# DSS_HWA_CFG register map
Vendor: Texas Instruments
Peripheral module from a debugger description file (folder awr2x44p).
Registers are 32-bit, read-only, no defined reset value unless marked. A register's access mark holds for its fields unless they carry their own. Offsets are as the file gives them; lines under a group give offsets from that group; [hi:lo] are bit positions; {n}, {i} and the like mark numbered series; 'fields as' and 'values as' point back to an identical list; <NAME> marks a mode.

## DSS_HWA_CFG
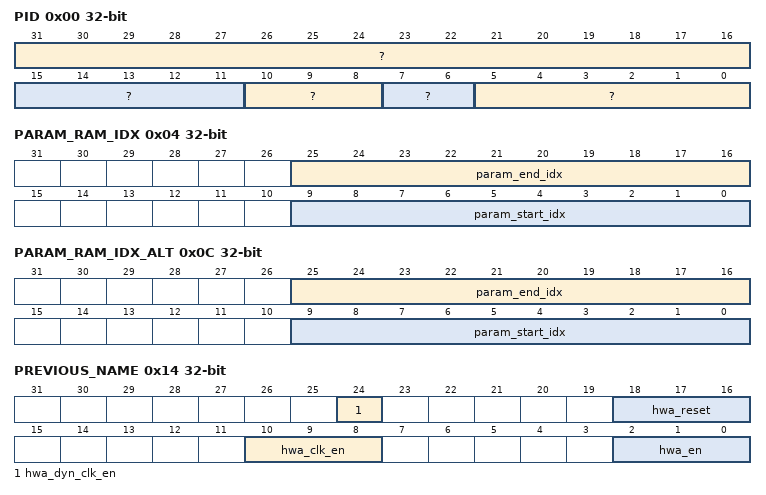
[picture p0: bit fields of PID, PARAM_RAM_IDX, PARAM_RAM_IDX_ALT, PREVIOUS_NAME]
0x00 PID
  [31:16] ?, [15:11] ?, [10:8] ?, [7:6] ?, [5:0] ?
0x04 PARAM_RAM_IDX rw
  [25:16] param_end_idx — The state machine starts at the parameter-set specified by PARAM_START_IDX and loads each parameter-set one after another and runs the accelerator as per that configuration. When the state machine reaches the parameter-set specified by PARAM_ENS_IDX, it loops back to the start index as specified by PARAM_START_IDX.Valid range : 0-63
  [9:0] param_start_idx — The state machine starts at the parameter-set specified by PARAM_START_IDX and loads each parameter-set one after another and runs the accelerator as per that configuration. When the state machine reaches the parameter-set specified by PARAM_ENS_IDX, it loops back to the start index as specified by PARAM_START_IDX..Valid range : 0-63
0x08 PARAM_RAM_LOOP rw
  [11:0] numloops — Number of loops: This register controls the number of times the State Machine will loop through the parameter-sets (from a programmed start index till a programmed end index) and run them. The maximum number of times the loop can be made is run is 4094. A value of zero programmed in this register means that the looping mechanism is disabled.
0x0C PARAM_RAM_IDX_ALT rw
  [25:16] param_end_idx — PARAM_END_IDX for alternate thread
  [9:0] param_start_idx — PARAM_START_IDX for alternate thread
0x10 PARAM_RAM_LOOP_ALT rw
  [11:0] numloops — NUMLOOPS for alternate thread
0x14 PREVIOUS_NAME rw
  [24] hwa_dyn_clk_en — Dynamic Clock-gating Control: Setting this register bit to '1' enables the capability to clock gate the 4 Radar Accelerator core IPs (FFT datapath,CFAR,Memory compression,Local Maxima) based on the ParamSet being executed.
  [18:16] hwa_reset — Software Reset Control: This register provides software reset control for the Radar Hardware Accelerator. The assertion of these register bits by the main processor will bring the Accelerator Engine to a known reset state. This is mostly applicable for resetting the accelerator in case of unexpected behavior. The sequence to be followed in case software reset is to write 111b to this register and then a 000b
  [10:8] hwa_clk_en — Clock-gating Control: This register controls the enable/disable for the clock of the Radar Accelerator. This register bit can be set to 0 to clock-gate the accelerator when not using the accelerator. Before enabling the accelerator or before configuring the accelerator s registers, this register bit should be set first to 111b, so that the clock is available
  [2:0] hwa_en — Enable/Disable Control: A value of ACC_ENABLE = 111b enables the Radar Hardware Accelerator and any other value of the register keeps the Accelerator Engine in disabled state. A 000b to 111b transition is expected to trigger a new Paramset execution
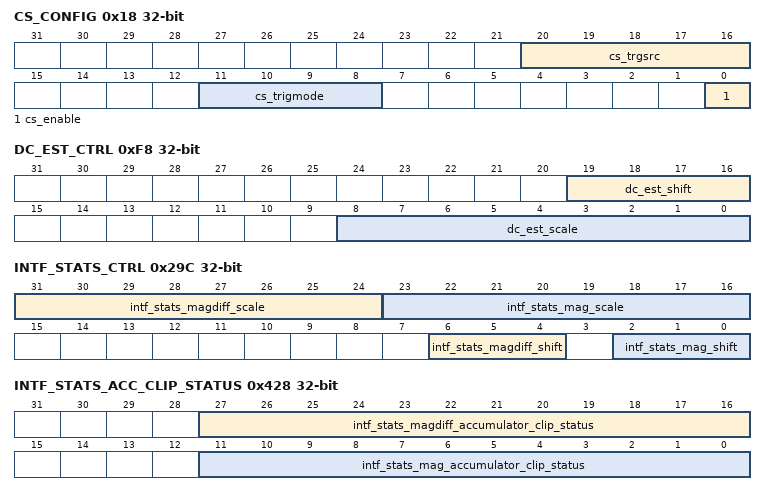
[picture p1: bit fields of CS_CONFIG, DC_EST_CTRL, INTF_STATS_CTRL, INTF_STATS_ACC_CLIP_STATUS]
0x18 CS_CONFIG rw
  [20:16] cs_trgsrc — In case of DMA trigger, this specifies which DMA channel (which bit in DMA2HWA_TRIG register) to wait for In case of HW-based trigger, this specifies which CSI2 trigger signal (out of the 20 possible trigger signals) to wait for
  [11:8] cs_trigmode — Trigger mode for context switching 0011b: DMA-based trigger (used in conjunction with DMA2HWA_TRIGGER and CS_TRIGSRC registers described below) 0100b: Hardware based trigger (used in conjunction with CS_TRIGSRC) Valid programmation 0-19, where 0 selct right most trigger and 19 selects left most trigger below {CSI2A_FRAME_START[1:0],CSI2A_LINE_END[7:0],CSI2B_FRAME_START[1:0],CSI2B_LINE_END[7:0]} 0101b: Software trigger (used in conjunction with CS_FW2ACC_TRIG register described below)
  [0] cs_enable — Master enable for the Conxtext switching feature.Setting this bit will allow context switching to ALT thread if it is enabled in the Param set
0x1C FW2DMA_TRIG rw
  [31:0] fw2dma_trigger — SW Override for HWA Trigger to DMA by the CPU It s a Self clearing bit
0x20 DMA2HWA_TRIG rw
  [31:0] dma2hwa_trigger — DMA trigger register: This register is relevant whenever DMA triggered mode is used (i.e., TRIGMODE = 011b). Whenever a DMA channel has finished copying input samples into the local memory of the accelerator and wants to trigger the accelerator, the procedure to follow is to use a second linked DMA channel to write a 16-bit one-hot signature into this register to trigger the accelerator. In DMA triggered mode, the State Machine keeps monitoring this 32-bit register and waits as long as a specific bit (see DMA2ACC_CHANNEL_TRIGSRC) in this register is zero. The second linked DMA channel writes a one-hot signature that sets the specific bit, so that the State Machine gets triggered and starts the accelerator operations for that parameter-set. It s a Self clearing bit
0x24 SIGDMACH0DONE
  [31:0] SIGDMACH0DONE — Signature for DMA channel 0 completion : 0x0000_0001 Linked DMA can copy from one of these SIG_DMACHx_DONE registers into DMA2HWA_TRIGGER register to set the appropriate register bit to signal the completion of DMA and trigger the accelerator
0x28 SIGDMACH1DONE
  [31:0] SIGDMACH1DONE — Signature for DMA channel 1 completion : 0x0000_0002
0x2C SIGDMACH2DONE
  [31:0] SIGDMACH2DONE — Signature for DMA channel 2 completion : 0x0000_0004
0x30 SIGDMACH3DONE
  [31:0] SIGDMACH3DONE — Signature for DMA channel 3 completion : 0x0000_0008
0x34 SIGDMACH4DONE
  [31:0] SIGDMACH4DONE — Signature for DMA channel 4 completion : 0x0000_0010
0x38 SIGDMACH5DONE
  [31:0] SIGDMACH5DONE — Signature for DMA channel 5 completion : 0x0000_0020
0x3C SIGDMACH6DONE
  [31:0] SIGDMACH6DONE — Signature for DMA channel 6 completion : 0x0000_0040
0x40 SIGDMACH7DONE
  [31:0] SIGDMACH7DONE — Signature for DMA channel 7 completion : 0x0000_0080
0x44 SIGDMACH8DONE
  [31:0] SIGDMACH8DONE — Signature for DMA channel 8 completion : 0x0000_0100
0x48 SIGDMACH9DONE
  [31:0] SIGDMACH9DONE — Signature for DMA channel 9 completion : 0x0000_0200
0x4C SIGDMACH10DONE
  [31:0] SIGDMACH10DONE — Signature for DMA channel 10 completion : 0x0000_0400
0x50 SIGDMACH11DONE
  [31:0] SIGDMACH11DONE — Signature for DMA channel 11 completion : 0x0000_0800
0x54 SIGDMACH12DONE
  [31:0] SIGDMACH12DONE — Signature for DMA channel 12 completion : 0x0000_1000
0x58 SIGDMACH13DONE
  [31:0] SIGDMACH13DONE — Signature for DMA channel 13 completion : 0x0000_2000
0x5C SIGDMACH14DONE
  [31:0] SIGDMACH14DONE — Signature for DMA channel 14 completion : 0x0000_4000
0x60 SIGDMACH15DONE
  [31:0] SIGDMACH15DONE — Signature for DMA channel 15 completion : 0x0000_8000
0x64 SIGDMACH16DONE
  [31:0] SIGDMACH16DONE — Signature for DMA channel 16 completion : 0x0001_0000
0x68 SIGDMACH17DONE
  [31:0] SIGDMACH17DONE — Signature for DMA channel 17 completion : 0x0002_0000
0x6C SIGDMACH18DONE
  [31:0] SIGDMACH18DONE — Signature for DMA channel 18 completion : 0x0004_0000
0x70 SIGDMACH19DONE
  [31:0] SIGDMACH19DONE — Signature for DMA channel 19 completion : 0x0008_0000
0x74 SIGDMACH20DONE
  [31:0] SIGDMACH20DONE — Signature for DMA channel 20 completion : 0x0010_0000
0x78 SIGDMACH21DONE
  [31:0] SIGDMACH21DONE — Signature for DMA channel 21 completion : 0x0020_0000
0x7C SIGDMACH22DONE
  [31:0] SIGDMACH22DONE — Signature for DMA channel 22 completion : 0x0040_0000
0x80 SIGDMACH23DONE
  [31:0] SIGDMACH23DONE — Signature for DMA channel 23 completion : 0x0080_0000
0x84 SIGDMACH24DONE
  [31:0] SIGDMACH24DONE — Signature for DMA channel 24 completion : 0x0100_0000
0x88 SIGDMACH25DONE
  [31:0] SIGDMACH25DONE — Signature for DMA channel 25 completion : 0x0200_0000
0x8C SIGDMACH26DONE
  [31:0] SIGDMACH26DONE — Signature for DMA channel 26 completion : 0x0400_0000
0x90 SIGDMACH27DONE
  [31:0] SIGDMACH27DONE — Signature for DMA channel 27 completion : 0x0800_0000
0x94 SIGDMACH28DONE
  [31:0] SIGDMACH28DONE — Signature for DMA channel 28 completion : 0x1000_0000
0x98 SIGDMACH29DONE
  [31:0] SIGDMACH29DONE — Signature for DMA channel 29 completion : 0x2000_0000
0x9C SIGDMACH30DONE
  [31:0] SIGDMACH30DONE — Signature for DMA channel 30 completion : 0x4000_0000
0xA0 SIGDMACH31DONE
  [31:0] SIGDMACH31DONE — Signature for DMA channel 31 completion : 0x8000_0000
0xA4 FW2HWA_TRIG_0 rw
  [0] fw2hwa_trigger_0 — Software trigger bit 0: This register bit is relevant whenever software triggered mode is used (i.e., TRIGMODE = 001b). The main processor software can set this register bit, so that the State Machine gets triggered and starts the accelerator operations for that parameter-set. It s a Self clearing bit
0xA8 FW2HWA_TRIG_1 rw
  [0] fw2hwa_trigger_1 — Software trigger bit 1: This register bit is relevant whenever software triggered mode is used (i.e., TRIGMODE = 111b). The main processor software can set this register bit, so that the State Machine gets triggered and starts the accelerator operations for that parameter-set. It s a Self clearing bit
0xAC CS_FW2ACC_TRIG rw
  [0] fw2hwa_trigger_cs — CPU can set this register bit to trigger a context switch when CS_TRIGMODE = 101b It s a Self clearing bit
{0xB0+4i} BPM_PATTERN_{i} rw (i=0..6)
  [31:0] bpm_pattern_{i} — BPM pattern [{32i+31}:{32i}]: Specifies the BPM pattern to be used to multiply the input samples if BPM removal is enabled
0xCC BPM_PATTERN_7 rw
  [31:0] bpm_pattern_7 — BPM pattern[255:224]: Specifies the BPM pattern to be used to multiply the input samples if BPM removal is enabled
0xD0 BPM_RATE rw
  [9:0] bpm_rate — BPM rate: Specifies the number of input samples corresponding to each BPM bit. Minimum valid value for this register is 1.
0xD4 PARAM_DONE_SET_STATUS_0
  [31:0] param_done_set_status_0 — Parameter-set done status[31:0]: This read-only status register can be used by the main processor to see which parameter-sets are complete that led to the interrupt to the main processor. The individual bits in this 64-bit status register indicate which of the 64 parameter-sets have completed.
0xD8 PARAM_DONE_SET_STATUS_1
  [31:0] param_done_set_status_1 — Parameter-set done status[63:32]: This read-only status register can be used by the main processor to see which parameter-sets are complete that led to the interrupt to the main processor. The individual bits in this 64-bit status register indicate which of the 64 parameter-sets have completed.
0xDC PARAM_DONE_CLR_0 rw
  [31:0] param_done_status_clr_0 — Status bits in PARAM_DONE_SET_STATUS are not automatically cleared, but they can be individually cleared by writing to 64-bit register PARAM_DONE_CLR. It s a Self clearing bit
0xE0 PARAM_DONE_CLR_1 rw
  [31:0] param_done_status_clr_1 — Status bits in PARAM_DONE_SET_STATUS are not automatically cleared, but they can be individually cleared by writing to 64-bit register PARAM_DONE_CLR. It s a Self clearing bit
0xE4 TRIGGER_SET_STATUS_0
  [31:0] trigger_set_status_0 — Debug register for trigger status[31:0]: This is a read-only status register, which indicates the trigger status of the accelerator, i.e., whether a specific DMA trigger or a CSI or a SW trigger was ever received (refer TRIGMODE in HW_ACC_PARAM register set). The mapping for 32 bits is as given below: {DMA2HWA_TRIGGER[31:0]}
0xE8 TRIGGER_SET_STATUS_1
  [31:0] trigger_set_status_1 — Debug register for trigger status[63:32]: This is a read-only status register, which indicates the trigger status of the accelerator, i.e., whether a specific DMA trigger or a CSI or a SW trigger was ever received (refer TRIGMODE in HW_ACC_PARAM register set). The mapping for 32 bits is as given below: {4'b0,CSI2A_FRAME_START[1:0],CSI2A_LINE_END[7:0],CSI2B_FRAME_START[1:0],CSI2B_LINE_END[7:0],FW2HWA_TRIGGER_CS,FW2HWA_TRIGGER_1,3'b0,FW2HWA_TRIGGER_0,1'b1}
0xEC TRIGGER_SET_IN_CLR_0 rw
  [0] trigger_set_in_clr_0 — Clear trigger_set_status : This register-bit when set clears the trigger status register TRIGGER_SET_STATUS_0 described above It s a Self clearing bit
0xF0 TRIGGER_SET_IN_CLR_1 rw
  [0] trigger_set_in_clr_1 — Clear trigger_set_status : This register-bit when set clears the trigger status register TRIGGER_SET_STATUS_1 described above It s a Self clearing bit
0xF4 DC_EST_RESET_SW rw
  [0] dc_est_reset_sw — Reset for all 12 DC estimation accumulators It s a Self clearing bit
0xF8 DC_EST_CTRL rw
  [19:16] dc_est_shift — Programmable shift applied to all 12 accumulator outputs. Cannot be bypassed. Output shifted by 2^(8 + 6+DCEST_SHIFT). For DCEST_SHIFT = 15 also gives 2^(28) and not 29 (saturate at 28)
  [8:0] dc_est_scale — 9-bit scale applied to all 12 accumulators. Multiplies the accumulator output by DCEST_SCALE/256.This is followed by right shift and truncation. Default value is 256 giving a scale of 1.0. Setting it to 128, gives a scale of 0.5
{0xFC+4i} DC_EST_I_{i}_VAL (i=0..11)
  [23:0] dc_est_i_{i}_val — This read only register provide the DC estimates I for bcnt= {i}
{0x12C+4i} DC_EST_Q_{i}_VAL (i=0..11)
  [23:0] dc_est_q_{i}_val — This read only register provide the DC estimates Q for bcnt= {i}
{0x15C+8i} DC_ACC_I_{i}_VAL_LSB (i=0..11)
  [31:0] dc_acc_i_{i}_val_lsb — This read only register provide the LSB 32 bits value of DC accumulator I channel value for bcnt={i}
{0x160+8i} DC_ACC_I_{i}_VAL_MSB (i=0..11)
  [3:0] dc_acc_i_{i}_val_msb — This read only register provide the MSB 4 bits value of DC accumulator I channel value for bcnt={i}
{0x1BC+8i} DC_ACC_Q_{i}_VAL_LSB (i=0..11)
  [31:0] dc_acc_q_{i}_val_lsb — This read only register provide the LSB 32 bits value of DC accumulator Q channel value for bcnt={i}
{0x1C0+8i} DC_ACC_Q_{i}_VAL_MSB (i=0..11)
  [3:0] dc_acc_q_{i}_val_msb — This read only register provide the MSB 4 bits value of DC accumulator Q channel value for bcnt={i}
0x21C DC_ACC_CLIP_STATUS
  [11:0] dc_acc_clip_status — This register contains the clip status of both I/Q of DC accumulators 0 to 11
0x220 DC_EST_CLIP_STATUS
  [11:0] dc_est_clip_status — This register contains the clip status of DC estimates (both I & Q combined)
0x224 DC_I0_SW rw
  [23:0] dc_i0_sw — SW programmed DC I value(for bcnt =0 ) used in DC subtraction
0x228 DC_I1_SW rw
  [23:0] dc_i1_sw — SW programmed DC I value(for bcnt =1) used in DC subtraction
0x22C DC_I2_SW rw
  [23:0] dc_i2_sw — SW programmed DC I value(for bcnt =2 ) used in DC subtraction
0x230 DC_I3_SW rw
  [23:0] dc_i3_sw — SW programmed DC I value(for bcnt =3) used in DC subtraction
{0x224+4i} DC_I{i}_SW rw (i=4..7)
  [23:0] dc_i{i}_sw — SW programmed DC I value(for bcnt ={i} ) used in DC subtraction
0x244 DC_I8_SW rw
  [23:0] dc_i8_sw — SW programmed DC I value(for bcnt =8) used in DC subtraction
0x248 DC_I9_SW rw
  [23:0] dc_i9_sw — SW programmed DC I value(for bcnt =9 ) used in DC subtraction
0x24C DC_I10_SW rw
  [23:0] dc_i10_sw — SW programmed DC I value(for bcnt =10 ) used in DC subtraction
0x250 DC_I11_SW rw
  [23:0] dc_i11_sw — SW programmed DC I value(for bcnt =11) used in DC subtraction
0x254 DC_Q0_SW rw
  [23:0] dc_q0_sw — SW programmed DC Q value(for bcnt =0 ) used in DC subtraction
0x258 DC_Q1_SW rw
  [23:0] dc_q1_sw — SW programmed DC Q value(for bcnt =1) used in DC subtraction
0x25C DC_Q2_SW rw
  [23:0] dc_q2_sw — SW programmed DC Q value(for bcnt =2 ) used in DC subtraction
0x260 DC_Q3_SW rw
  [23:0] dc_q3_sw — SW programmed DC Q value(for bcnt =3) used in DC subtraction
{0x254+4i} DC_Q{i}_SW rw (i=4..7)
  [23:0] dc_q{i}_sw — SW programmed DC Q value(for bcnt ={i} ) used in DC subtraction
0x274 DC_Q8_SW rw
  [23:0] dc_q8_sw — SW programmed DC Q value(for bcnt =8) used in DC subtraction
0x278 DC_Q9_SW rw
  [23:0] dc_q9_sw — SW programmed DC Q value(for bcnt =9 ) used in DC subtraction
0x27C DC_Q10_SW rw
  [23:0] dc_q10_sw — SW programmed DC Q value(for bcnt =10 ) used in DC subtraction
0x280 DC_Q11_SW rw
  [23:0] dc_q11_sw — SW programmed DC Q value(for bcnt =11) used in DC subtraction
0x284 DC_SUB_CLIP
  [0] DC_SUB_CLIP — Indicates the DC subtraction clip status
{0x280+4i} DC_RESERVED_{i} rw (i=2..5)
  [31:0] dc_sub_reserved_{i} — Reserved for future addition
0x298 INTF_STATS_RESET_SW rw
  [0] intf_stats_reset_sw — SW reset for Interference stats module. It s a self clearing bit.
0x29C INTF_STATS_CTRL rw
  [31:24] intf_stats_magdiff_scale — Unsigned scaler (5.3) applied to INTERFSUM_MAGDIFFn from interference statistics block. Default 8= scale of 1.0
  [23:16] intf_stats_mag_scale — Unsigned scaler (5.3) applied to INTERFSUM_MAGn from interference statistics block. Default 8= scale of 1.0
  [6:4] intf_stats_magdiff_shift — Right shift applied after scaling - 2^(6+INTERFSUM_MAGDIFF_SHIFT). Can t be more than 2^(12).
  [2:0] intf_stats_mag_shift — Right shift applied after scaling - 2^(6+INTERSUM_MAGS_SHIFT). Can t be more than 2^(12).
{0x2A0+4i} INTF_LOC_THRESH_MAG{i}_VAL (i=0..11)
  [23:0] intf_loc_thresh_mag{i}_val — Interference magnitude threshold value from Interference stats module ( read only) for bcnt ={i}
{0x2D0+4i} INTF_LOC_THRESH_MAGDIFF{i}_VAL (i=0..11)
  [23:0] intf_loc_thresh_magdiff{i}_val — Interference magnitude difference threshold value from Interference stats module ( read only) for bcnt ={i}
0x300 INTF_LOC_COUNT_ALL_CHIRP
  [11:0] intf_loc_count_all_chirp — Number of samples that exceeded the threshold in a chirp
0x304 INTF_LOC_COUNT_ALL_FRAME
  [19:0] intf_loc_count_all_frame — Number of samples that exceeded the threshold in a frame
0x308 INTF_STATS_MAG_ACC_0_LSB
  [31:0] intf_stats_mag_acc_0_lsb — This read only register contains the accumulator value of interference magnitude(LSB 32 bits) for bcnt = 0
0x30C INTF_STATS_MAG_ACC_0_MSB
  [3:0] intf_stats_mag_acc_0_msb — This read only register contains the accumulator value of interference magnitude(MSB 4 bits) for bcnt = 0
0x310 INTF_STATS_MAG_ACC_1_LSB
  [31:0] intf_stats_mag_acc_1_lsb — This read only contains the accumulator value of interference magnitude (LSB 32 bits) for bcnt = 1
0x314 INTF_STATS_MAG_ACC_1_MSB
  [3:0] intf_stats_mag_acc_1_msb — This read only contains the accumulator value of interference magnitude (MSB 4 bits) for bcnt = 1
0x318 INTF_STATS_MAG_ACC_2_LSB
  [31:0] intf_stats_mag_acc_2_lsb — This read only contains the accumulator value of interference magnitude (LSB 32 bits) for bcnt = 2
0x31C INTF_STATS_MAG_ACC_2_MSB
  [3:0] intf_stats_mag_acc_2_msb — This read only register contains the accumulator value of interference magnitude (MSB 4 bits) for bcnt = 2
0x320 INTF_STATS_MAG_ACC_3_LSB
  [31:0] intf_stats_mag_acc_3_lsb — This read only register contains the accumulator value of the interference magnitude( for LSB 32 bits) for bcnt = 3
0x324 INTF_STATS_MAG_ACC_3_MSB
  [3:0] intf_stats_mag_acc_3_msb — This read only register contains the accumulator value of the interference magnitude(for MSB 4 bits) for bcnt = 3
{0x308+8i} INTF_STATS_MAG_ACC_{i}_LSB (i=4..9)
  [31:0] intf_stats_mag_acc_{i}_lsb — This read only register contains the accumulator value of the interference magnitude (LSB 32 bits) for bcnt = {i}
{0x30C+8i} INTF_STATS_MAG_ACC_{i}_MSB (i=4..6)
  [3:0] intf_stats_mag_acc_{i}_msb — This read only register contains the accumulator value of the interference magnitude (MSB 4 bits)for bcnt = {i}
0x344 INTF_STATS_MAG_ACC_7_MSB
  [3:0] intf_stats_mag_acc_7_msb — This read only register contains the accumulator value of the interference magnitude (MSB4 bits)for bcnt = 7
{0x30C+8i} INTF_STATS_MAG_ACC_{i}_MSB (i=8..11)
  [3:0] intf_stats_mag_acc_{i}_msb — This read only register contains the accumulator value of the interference magnitude (MSB 4 bits) for bcnt = {i}
0x358 INTF_STATS_MAG_ACC_10_LSB
  [31:0] intf_stats_mag_acc_10_lsb — This read only register contains the accumulator value of the interference magnitude (LSB 32 bits)for bcnt = 10
0x360 INTF_STATS_MAG_ACC_11_LSB
  [31:0] intf_stats_mag_acc_11_lsb — This read only register contains the accumulator value of the interference magnitude (LSB 32 bits)for bcnt = 11
{0x368+8i} INTF_STATS_MAGDIFF_ACC_{i}_LSB (i=0..3)
  [31:0] intf_stats_magdiff_acc_{i}_lsb — This read only register contains the accumulator value of the interference magnitude difference (LSB 32 bits) for bcnt = {i}
{0x36C+8i} INTF_STATS_MAGDIFF_ACC_{i}_MSB (i=0..11)
  [3:0] intf_stats_magdiff_acc_{i}_msb — This read only register contains the accumulator value of the interference magnitude difference (MSB 4 bits) for bcnt = {i}
0x388 INTF_STATS_MAGDIFF_ACC_4_LSB
  [31:0] intf_stats_magdiff_acc_4_lsb — This read only register contains the accumulator value of the interference magnitude difference (LSB 32 bits) accumulator for bcnt = 4
{0x368+8i} INTF_STATS_MAGDIFF_ACC_{i}_LSB (i=5..11)
  fields as INTF_STATS_MAGDIFF_ACC_0_LSB
{0x3C8+4i} INTF_LOC_THRESH_MAG{i}_SW rw (i=0..11)
  [23:0] intf_loc_thresh_mag{i}_sw — SW programmed interface threshold magnitude for bcnt={i}
{0x3F8+4i} INTF_LOC_THRESH_MAGDIFF{i}_SW rw (i=0..11)
  [23:0] intf_loc_thresh_magdiff{i}_sw — SW programmed interface threshold magnitude difference for bcnt={i}
0x428 INTF_STATS_ACC_CLIP_STATUS
  [27:16] intf_stats_magdiff_accumulator_clip_status — Interference magnitue difference accumulator Clip status
  [11:0] intf_stats_mag_accumulator_clip_status — Interference magnitue accumulator Clip status
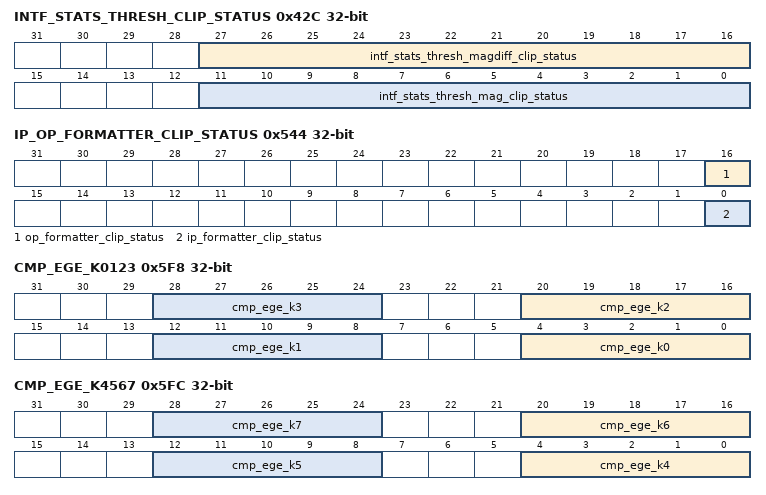
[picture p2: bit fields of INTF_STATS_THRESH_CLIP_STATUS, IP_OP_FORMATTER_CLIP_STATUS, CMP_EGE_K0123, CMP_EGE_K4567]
0x42C INTF_STATS_THRESH_CLIP_STATUS
  [27:16] intf_stats_thresh_magdiff_clip_status — Interference magnitude difference threshold Clip status
  [11:0] intf_stats_thresh_mag_clip_status — Interference magnitude threshold Clip status
0x430 INTF_MITG_WINDOW_PARAM_0 rw
  [4:0] intf_mitg_window_param_0 — This is a programmable array of window parameters. Each window parameter is an unsigned 5 bit integer. The total length of the array is 5. The BFR of the array is given by the matlab code : val = round(hanning(12)*32) INTF_MITG_WINDOW_PARAM = val(1:5);
{0x430+4i} INTF_MITG_WINDOW_PARAM_{i} rw (i=1..4)
  [4:0] intf_mitg_window_param_{i} — Refer description of INTF_MITG_WINDOW_PARAM_0
0x444 INTF_STATS_SUM_MAG_VAL
  [23:0] intf_stats_sum_mag_val — Indicates the sum of mag values ; Only Configured BCNT mag values are added
0x448 INTF_STATS_SUM_MAG_VAL_CLIP_STATUS
  [0] intf_stats_sum_mag_val_clip_status — Indicates the clip status of sum of mag values
0x44C INTF_STATS_SUM_MAGDIFF_VAL
  [23:0] intf_stats_sum_magdiff_val — Indicates the sum of magdiff values ; Only Configured BCNT magdiff values are added
0x450 INTF_STATS_SUM_MAGDIFF_VAL_CLIP_STATUS
  [0] intf_stats_sum_magdiff_val_clip_status — indicates the clip status of sum of magdiff values
0x454 INTERF_RESERVED_5 rw
  [31:0] interf_reserved_5 — Reserved for future addition
{0x458+4i} ICMULT_SCALE{i} rw (i=0..11)
  [20:0] icmult_scale{i} — Complex scalars used in CMULT_MODE = 0101, 0110 & 0111 In CMULT_MODE : 0101 , If set CMULT_SCALE_EN is 1, the input samples are multiplied by a different complex scalar ICMULTSCALE0, QMULTSCALE0 to ICMULTSCALE11, QMULTSCALE11 per-iteration based on REG_BCNT. Else, a constant complex scalar ICMULTSCALE0 and QCMULTSCALE0 is applied to all sample across all iterations. In CMULT_MODE : 0110 or 0111, if CMULT_SCALE_EN is 1, then input samples are multiplied successively by ICMULTSCALE0, QMULTSCALE0 to ICMULTSCALE11, QMULTSCALE11 per iteration. Complex scalar to be multiplier is ACNT modulo 12.
{0x488+4i} QCMULT_SCALE{i} rw (i=0..11)
  [20:0] qcmult_scale{i} — Complex scalars used in CMULT_MODE = 0101, 0110 & 0111 In CMULT_MODE : 0101 , If set CMULT_SCALE_EN is 1, the input samples are multiplied by a different complex scalar ICMULTSCALE0, QMULTSCALE0 to ICMULTSCALE11, QMULTSCALE11 per-iteration based on REG_BCNT. Else, a constant complex scalar ICMULTSCALE0 and QCMULTSCALE0 is applied to all sample across all iterations. In CMULT_MODE : 0110 or 0111, if CMULT_SCALE_EN is 1, then input samples are multiplied successively by ICMULTSCALE0, QMULTSCALE0 to ICMULTSCALE11, QMULTSCALE11 per iteration. Complex scalar to be multiplier is ACNT modulo 12.
0x4B8 TWID_INCR_DELTA_FRAC rw
  [9:0] twid_incr_delta_frac — Used in complex multiplier mode 10 Delta Fractional frequency increment per param-set looping Instantaneous frequency is (TWIDINCR << 10) +TWID_INCR_DELTA_ FRAC*c, c is current execution count of the parameter set.
0x4BC RECWIN_RESET_SW rw
  [0] recwin_reset_sw — This resets the param set counter / execution counter used in Complex multiplier mode 8 . It s a self clearing bit.
0x4C0 TWID_INCR_DELTA_FRAC_RESET_SW rw
  [0] twid_incr_delta_frac_reset_sw — This resets the param set counter used in Complex multiplier mode 10 . It s a Self clearing bit
0x4C4 TWID_INCR_DELTA_FRAC_CLIP_STATUS
  [0] twid_incr_delta_frac_clip_status — Indicates the clip status for TWID_INCR_DELTA_FRAC accumulator
0x4C8 RECWIN_INIT_KVAL rw
  [11:0] recwin_init_kval — Indicates the initialization value of execution counter in recursive window mode . Execution counter value is initialized when recwin_reset_sw is 1'b1
0x4CC CMULT_RESERVED_2 rw
  [31:0] cmult_reserved_2 — Reserved for future addition
0x4D0 CHAN_COMB_SIZE rw
  [7:0] chan_comb_size — Number of samples after combination
{0x4D4+4i} CHAN_COMB_VEC_{i} rw (i=0..7)
  [31:0] chan_comb_vec_{i} — Channel combination MASK for {32i} to {32i+31} samples Vector indicating the samples indices that need to be combined. A 01 or 10 transition demarcates the groups. if CHAN_COMB_VEC = 0xF030000000000000 sums the first 4 samples and outputs one sample, sums 5th-9th samples and passes one sample, combines 10th-12th samples, outputs one sample and then streams the rest of the input
0x4F4 CHANNEL_COMB_CLIP_STATUS
  [0] channel_comb_clip_status — Indicates the clip status of the channel combination
0x4F8 ZERO_INSERT_NUM rw
  [7:0] zero_insert_num — Number of zeros to be inserted in an iteration
{0x4FC+4i} ZERO_INSERT_MASK_{i} rw (i=0..5)
  [31:0] zero_insert_mask_{i} — Zero insert mask for samples {32i} to {32i+31} A bit-field of 0 inserts a zero at location based on bit-field index. 1 means the input is passed through. Up-stream and down-stream processing is stalled during the zero insertion
0x514 ZERO_INSERT_MASK_6 rw
  [31:0] zero_insert_mask_6 — Zero insert mask for samples 192 to 223 A bit field of 0 inserts a zero at location based on bit-field index. 1 means the input is passed through. Up-stream and down-stream processing is stalled during the zero insertion
0x518 ZERO_INSERT_MASK_7 rw
  [31:0] zero_insert_mask_7 — Zero insert mask for samples 224 to 255 A bit-field of 0 inserts a zero at location based on bit-field index. 1 means the input is passed through. Up-stream and down-stream processing is stalled during the zero insertion
{0x518+4i} ZERO_INSERT_RESERVED_{i} rw (i=1..4)
  [31:0] zero_insert_reserved_{i} — Reserved for future addition
0x52C LFSR_SEED rw
  [28:0] lfsr_seed — Seed for LFSR (random pattern): For twiddle factor dithering, there is an LFSR that is used, whose seed value is loaded by writing to this 29-bit LFSRSEED register. The LFSRSEED register should be set to any non-zero value, say 0x1234567
0x530 LFSR_LOAD rw
  [0] lfsr_load — Its self clearing bit . It should be set for loading the LFSR_SEED. It s a self clearing bit
0x534 DITHER_TWID_EN rw
  [0] dither_twid_en — Twiddle factor dithering enable: This register-bit is used to enable and disable dithering of twiddle factors in the FFT. The twiddle factors are 24-bits wide (24-bits for each I and Q), but they are quantized to 21-bits before twiddle factor multiplication. This quantization is implemented with dithering on the LSB, to avoid periodic quantization pattern affecting SFDR performance of the FFT. TI recommends keeping this register bit set to 1 (for example, dithering enabled), with appropriate LSFR seed loaded (see the following).
0x538 FFT_CLIP
  [12:0] fft_clip — FFT Clip Status (read-only): This is a read-only status register, which indicates any saturation/clipping events that have happened in the FFT butterfly stages. Note that each of the individual butterfly stages in the FFT can be programmed to either saturate the MSB or round the LSB. Whenever saturation of MSB is used in any stage, there is a possibility that that stage can saturate or clip samples. In that case, this saturation event is indicated in the corresponding bit in this status register, so that the Cortex-R4F processor can read it. If multiple FFTs are performed, this status register includes any saturation events happening in any of them. This status register can only be cleared by the R4F, by setting another single-bit register CLR_FFTCLIP, so that the saturation status indication gets cleared back to 0 and any subsequent saturation events can be freshly monitored. The MSB of this register indicates clip status corresponding to the radix 3 butterfly.
0x53C CLR_FFTCLIP rw
  [0] clr_fftclip — Clear FFT Clip Status register: This register bit, when set, clears the FFTCLIP register. It s a self clearing bit
0x540 CLR_CLIP_MISC rw
  [0] clr_clip_status — This clears the following clip register channel_comb_clip_status dc_acc_clip_status dc_est_clip_status intf_stats_mag_accumulator_clip_status intf_stats_magdiff_accumulator_clip_status intf_stats_thresh_mag_clip_status intf_stats_thresh_magdiff_clip_status twid_incr_delta_frac_clip_status ip_formatter_clip_status op_formatter_clip_status intf_stats_sum_mag_val_clip_status intf_stats_sum_magdiff_val_clip_status dc_sub_clip Its a self clearing bit
0x544 IP_OP_FORMATTER_CLIP_STATUS
  [16] op_formatter_clip_status — Indicates the output formatter clip status
  [0] ip_formatter_clip_status — Indicates the input formatter clip status
{0x544+4i} FFT_RESERVED_{i} rw (i=1..3)
  [31:0] fft_reserved_{i} — Reserved for future addition
{0x550+4i} MAX{i}_VALUE (i=1..4)
  [23:0] max{i}_value — These registers contain the max value on a per-iteration basis. These registers are meaningful only when Magnitude or Log-Magnitude is enabled. Only the max values for up to four iterations are recorded in these registers. For larger number of iterations, max values are wriiten into destination memory by configuring FFT_OUTPUT_MODE
{0x560+4i} MAX{i}_INDEX (i=1..4)
  [11:0] max{i}_index — These registers contain the max index on a per-iteration basis, corresponding to each max value in the MAXn_VALUE registers.
{0x56C+8i} I_SUM{i}_LSB (i=1..4)
  [31:0] i_sum{i}_lsb — I Sum value {i} LSB 32 bits These registers contain the sum of the I outputs and Q outputs on a per-iteration basis. Only the statistics for up to four iterations are recorded in these registers. For larger number of iterations, use statistics output mode (FFT_OUTPUT_MODE ) to write to destination memory
{0x570+8i} I_SUM{i}_MSB (i=1..4)
  [3:0] i_sum{i}_msb — I Sum value {i} MSB 4 bits These registers contain the sum of the I outputs and Q outputs on a per-iteration basis. Only the statistics for up to four iterations are recorded in these registers. For larger number of iterations, use statistics output mode (FFT_OUTPUT_MODE ) to write to destination memory
{0x58C+8i} Q_SUM{i}_LSB (i=1..4)
  [31:0] q_sum{i}_lsb — Q Sum value {i} LSB 32 bits These registers contain the sum of the I outputs and Q outputs on a per-iteration basis. Only the statistics for up to four iterations are recorded in these registers. For larger number of iterations, use statistics output mode (FFT_OUTPUT_MODE ) to write to destination memory
{0x590+8i} Q_SUM{i}_MSB (i=1..4)
  [3:0] q_sum{i}_msb — Q Sum value {i} MSB 4 bits These registers contain the sum of the I outputs and Q outputs on a per-iteration basis. Only the statistics for up to four iterations are recorded in these registers. For larger number of iterations, use statistics output mode (FFT_OUTPUT_MODE ) to write to destination memory
0x5B4 FFTSUMDIV rw
  [4:0] fftsumdiv — Right-shifting for Sum statistic: This register specifies the number of bits to right-shift the sum statistic before it is written to destination memory. The internal sum statistic register is 36-bits wide (allowing 12 bits of MSB growth of the 24-bit data path), but this statistics value needs to be scaled down to 24 bits to match the data path width going to the Output Formatter. This register specifies how many LSBs to drop to convert the sum statistics to 24-bit value.
0x5B8 MAX2D_OFFSET_DIM1 rw
  [23:0] max2d_offset_dim1 — Offset to be added to dimension 1 Maxima results. This offset will be applied to all the maxima results in the iteration dimension. Needs to be configured to 0 in case no offset is required.
0x5BC MAX2D_OFFSET_DIM2 rw
  [23:0] max2d_offset_dim2 — Offset to be added to dimension 2 Maxima results. This offset will be applied to all the maxima results in the sample dimension. Needs to be configured to 0 in case no offset is required.
0x5C0 CDF_CNT_THRESH rw
  [11:0] cdf_cnt_thresh — This register is applicable in CDF_CNT_THRESH mode of operation. CDF is computed over the histogram till the value of the CDF just exceeds the CDF_CNT_THRESH specified by the user. This register can take values from 0 to 1023.
{0x5C0+4i} STATS_RESERVED_{i} rw (i=1..5)
  [31:0] stats_reserved_{i} — Future use
0x5D8 CFAR_PEAKCNT
  [11:0] cfar_peakcnt — CFAR detected peak count: This is a read-only register that contains the number of detected peaks that are logged in the destination memory, when CFAR Engine is configured in Detected Peaks List mode. In the Detected Peaks List mode, since only the detected peaks are logged in the destination memory, this read-only register provides the number of detected peaks that are logged to the main processor, so that the main processor can determine how many entries to read from the destination memory.
0x5DC CFAR_DET_THR rw
  [23:0] cfar_det_thr — To be added
0x5E0 CFAR_TEST_REG rw
  [23:0] cfar_test_reg — To be added
0x5E4 CFAR_THRESH rw
  [17:0] cfar_thresh — Threshold scale factor: This register is used to specify the threshold scale factor. This value is used to either multiply or add to the surrounding noise average to determine the threshold used for detection of the present cell under test. If logarithmic CFAR mode is disabled (in magnitude or magnitude-squared mode), then the register value is multiplied with the surrounding noise average to determine the threshold, else it is added to the surrounding noise average. In the former case, this 18-bit register is interpreted as a 14.4 value. In the latter case (logarithmic mode), the 18-bit register is interpreted as a 7.11 value.
{0x5E4+4i} CFAR_RESERVED_{i} rw (i=1..4)
  [31:0] cfar_reserved_{i} — Future use
0x5F8 CMP_EGE_K0123 rw
  [8n+4:8n] cmp_ege_k{n} (n=0..3) — {n}th K-param value should be loaded here which would be used in the First-pass of EGE Compression
0x5FC CMP_EGE_K4567 rw
  [8n-28:8n-32] cmp_ege_k{n} (n=4..7) — {n}th K-param value should be loaded here which would be used in the First-pass of EGE Compression
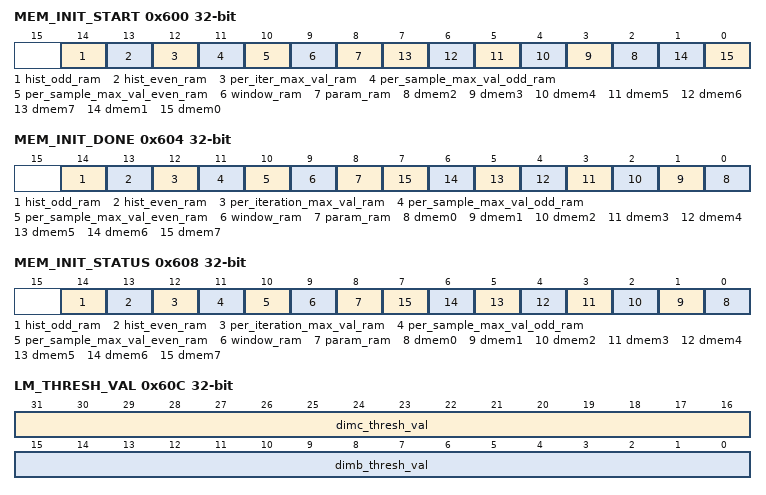
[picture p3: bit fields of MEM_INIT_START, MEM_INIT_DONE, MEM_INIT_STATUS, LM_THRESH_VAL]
0x600 MEM_INIT_START rw
  [14] hist_odd_ram — writing 1'b1 would start the memory initialization for the Histogram memory 2 It s a self clearing bit
  [13] hist_even_ram — writing 1'b1 would start the memory initialization for the Histogram memory 1 It s a self clearing bit
  [12] per_iter_max_val_ram — writing 1'b1 would start the memory initialization for the 2D MAX per iteration RAM It s a self clearing bit
  [11] per_sample_max_val_odd_ram — writing 1'b1 would start the memory initialization for the 2D MAX per sample RAM 2 It s a self clearing bit
  [10] per_sample_max_val_even_ram — writing 1'b1 would start the memory initialization for the 2D MAX per sample RAM 1 It s a self clearing bit
  [9] window_ram — writing 1'b1 would start the memory initialization for the window memory It s a self clearing bit
  [8] param_ram — writing 1'b1 would start the memory initialization for the Param memory It s a self clearing bit
  [n] dmem{n} (n=2..7) — writing 1'b1 would start the memory initialization for the DMEM{n} It s a self clearing bit
  [1] dmem1 — writing 1'b1 would start the memory initialization for the DMEM1. It s a self clearing bit
  [0] dmem0 — writing 1'b1 would start the memory initialization for the DMEM0 It s a self clearing bit
0x604 MEM_INIT_DONE rw
  [14] hist_odd_ram — Will be 1'b1 after cmpletion of memory initialization for hist_odd_ram
  [13] hist_even_ram — Will be 1'b1 after cmpletion of memory initialization for hist_even_ram
  [12] per_iteration_max_val_ram — Will be 1'b1 after cmpletion of memory initialization for per_iteration_max_val_ram
  [11] per_sample_max_val_odd_ram — Will be 1'b1 after cmpletion of memory initialization for per_sample_max_val_odd_ram
  [10] per_sample_max_val_even_ram — Will be 1'b1 after cmpletion of memory initialization for per_sample_max_val_even_ram
  [9] window_ram — Will be 1'b1 after cmpletion of memory initialization for window_ram
  [8] param_ram — Will be 1'b1 after cmpletion of memory initialization for param_ram
  [n] dmem{n} (n=0..7) — Will be 1'b1 after cmpletion of memory initialization for dmem{n}
0x608 MEM_INIT_STATUS
  [14] hist_odd_ram — Will be 1'b1 during memory initialization for hist_odd_ram
  [13] hist_even_ram — Will be 1'b1 during memory initialization for hist_even_ram
  [12] per_iteration_max_val_ram — Will be 1'b1 during memory initialization for per_iteration_max_val_ram
  [11] per_sample_max_val_odd_ram — Will be 1'b1 during memory initialization for per_sample_max_val_odd_ram
  [10] per_sample_max_val_even_ram — Will be 1'b1 during memory initialization for per_sample_max_val_even_ram
  [9] window_ram — Will be 1'b1 during memory initialization for window_ram
  [8] param_ram — Will be 1'b1 during memory initialization for param_ram
  [n] dmem{n} (n=0..7) — Will be 1'b1 during memory initialization for dmem{n}
0x60C LM_THRESH_VAL rw
  [31:16] dimc_thresh_val — Threshold value configured for Dimension C
  [15:0] dimb_thresh_val — Threshold value configured for Dimension B
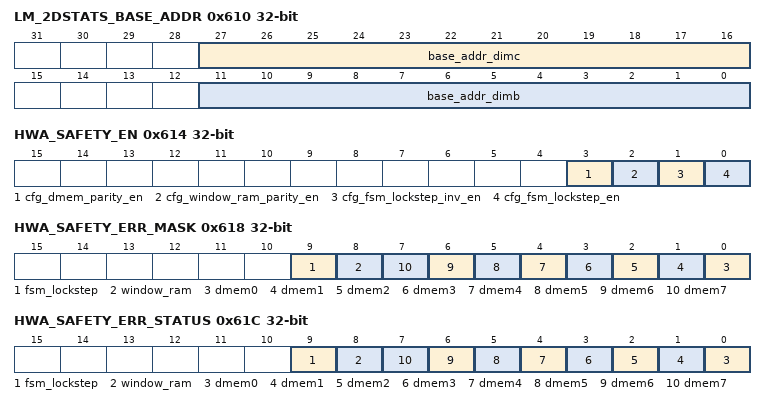
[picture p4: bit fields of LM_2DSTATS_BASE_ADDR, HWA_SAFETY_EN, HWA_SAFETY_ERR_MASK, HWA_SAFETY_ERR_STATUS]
0x610 LM_2DSTATS_BASE_ADDR rw
  [27:16] base_addr_dimc — Base Address in Stats RAM for the Threshold values corresponding to dimension C
  [11:0] base_addr_dimb — Base Address in Stats RAM for the Threshold values corresponding to dimension B
0x614 HWA_SAFETY_EN rw
  [3] cfg_dmem_parity_en — Writing 1'b1 would enable the parity chekcer for the 8 DMEM memories
  [2] cfg_window_ram_parity_en — Writing 1'b1 enables parity for windowing RAM
  [1] cfg_fsm_lockstep_inv_en — Writing 1'b1 will invert the redundant FSM outputs. This can be used for selftest of FSM lockstep error interrupt. This bit is self clearing bit
  [0] cfg_fsm_lockstep_en — Writing 1'b1 would enable the lockstep logic for FSM
0x618 HWA_SAFETY_ERR_MASK rw
  [9] fsm_lockstep — When 1'b1 : FSM lockstep error is masked 1'b0 : FSM lockstep error is not masked
  [8] window_ram — When 1'b1 : window RAM parity error is masked 1'b0 : window RAM parity error is not masked
  [n] dmem{n} (n=0..7) — When 1'b1 : DMEM{n} parity error is masked 1'b0 : DMEM{n} parity error is not masked
0x61C HWA_SAFETY_ERR_STATUS rw
  [9] fsm_lockstep — Indicates the FSM lockstep error (Masked status)
  [8] window_ram — Indicates the parity error in window RAM (Masked status)
  [n] dmem{n} (n=0..7) — Indicates the parity error in dmem{n} (Masked status)
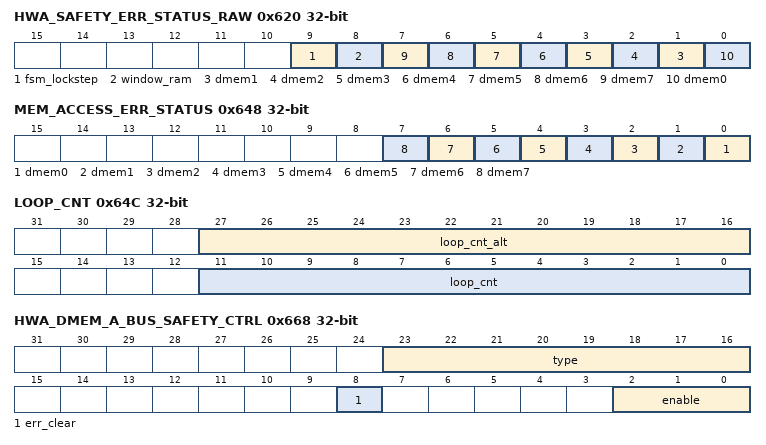
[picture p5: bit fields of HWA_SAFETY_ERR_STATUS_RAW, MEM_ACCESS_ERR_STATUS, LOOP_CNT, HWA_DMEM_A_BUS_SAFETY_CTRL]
0x620 HWA_SAFETY_ERR_STATUS_RAW rw
  [9] fsm_lockstep — Indicates the FSM lockstep error (raw status) Set irrespective of HWA_SAFETY_ERR_MASK bit 9
  [8] window_ram — Indicates the parity error in window RAM(raw status) Set irrespective of HWA_SAFETY_ERR_MASK bit 8
  [n] dmem{n} (n=1..7) — Indicates the parity error in dmem{n}(raw status) Set irrespective of HWA_SAFETY_ERR_MASK bit {n}
  [0] dmem0 — Indicates the parity error in dmem0(raw status). Set irrespective of HWA_SAFETY_ERR_MASK bit 0
{0x624+4i} HWA_SAFETY_DMEM{i}_ERR_ADDR (i=0..7)
  [9:0] dmem{i}_err_addr — Captures the address where parity error occured for dmem{i}
0x644 HWA_SAFETY_WINDOW_RAM_ERR_ADDR
  [10:0] window_ram_err_addr — Captures the address where parity error occured for window RAM
0x648 MEM_ACCESS_ERR_STATUS rw
  [n] dmem{n} (n=0..7) — Indicates if more than 1 master ( DMA,CM4,Accelerator) are trying to access the dmem{n} at the same time
0x64C LOOP_CNT
  [27:16] loop_cnt_alt — Loop count for alternate thread
  [11:0] loop_cnt — Loop count
0x650 PARAMADDR
  [5:0] paramaddr — Index of the current parameter set being executed from PARAM RAM .
0x654 PARAMADDR_CPUINTR0
  [5:0] paramaddr — Index of the parameter set when PARAM_DONE_INTR0 is generated
0x658 PARAMADDR_CPUINTR1
  [5:0] paramaddr — Index of the parameter set when PARAM_DONE_INTR1 is generated
0x65C FSM_STATE
  [2:0] fsm_state — Current state of the state machine
0x660 SINGLE_STEP_EN rw
  [0] single_step_en — Single step enable 1'b1 : the state machine executes one parameter-set at a time and wait for the single step trigger every time
0x664 SINGLE_STEP_TRIG rw
  [0] single_step_trig — This is a self clearing sofware trigger bit . When single_step_en is 1 , the state machine executes one parameter-set at a time and wait for the single step trigger every time
0x668 HWA_DMEM_A_BUS_SAFETY_CTRL access per field
  [23:16] type ro — Refer to TPR12 Substem Microarch document for more details
  [8] err_clear rw — Refer to TPR12 Substem Microarch document for more details
  [2:0] enable rw — Refer to TPR12 Substem Microarch document for more details
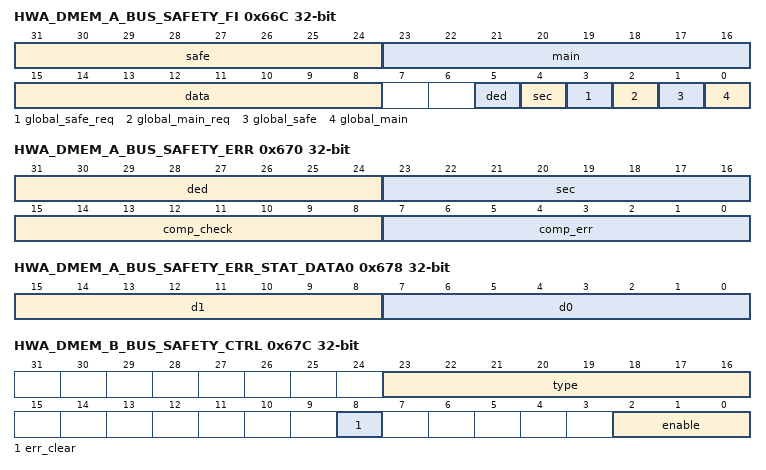
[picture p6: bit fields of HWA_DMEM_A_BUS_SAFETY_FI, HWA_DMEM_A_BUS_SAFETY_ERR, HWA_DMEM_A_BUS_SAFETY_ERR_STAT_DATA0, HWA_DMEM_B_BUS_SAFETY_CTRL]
0x66C HWA_DMEM_A_BUS_SAFETY_FI rw
  [31:24] safe — Refer to TPR12 Substem Microarch document for more details
  [23:16] main — Refer to TPR12 Substem Microarch document for more details
  [15:8] data — Refer to TPR12 Substem Microarch document for more details
  [5] ded — Refer to TPR12 Substem Microarch document for more details
  [4] sec — Refer to TPR12 Substem Microarch document for more details
  [3] global_safe_req — Refer to TPR12 Substem Microarch document for more details
  [2] global_main_req — Refer to TPR12 Substem Microarch document for more details
  [1] global_safe — Refer to TPR12 Substem Microarch document for more details
  [0] global_main — Refer to TPR12 Substem Microarch document for more details
0x670 HWA_DMEM_A_BUS_SAFETY_ERR
  [31:24] ded — Refer to TPR12 Substem Microarch document for more details
  [23:16] sec — Refer to TPR12 Substem Microarch document for more details
  [15:8] comp_check — Refer to TPR12 Substem Microarch document for more details
  [7:0] comp_err — Refer to TPR12 Substem Microarch document for more details
0x678 HWA_DMEM_A_BUS_SAFETY_ERR_STAT_DATA0
  [15:8] d1 — Refer to TPR12 Substem Microarch document for more details
  [7:0] d0 — Refer to TPR12 Substem Microarch document for more details
0x67C HWA_DMEM_B_BUS_SAFETY_CTRL access per field
  fields as HWA_DMEM_A_BUS_SAFETY_CTRL
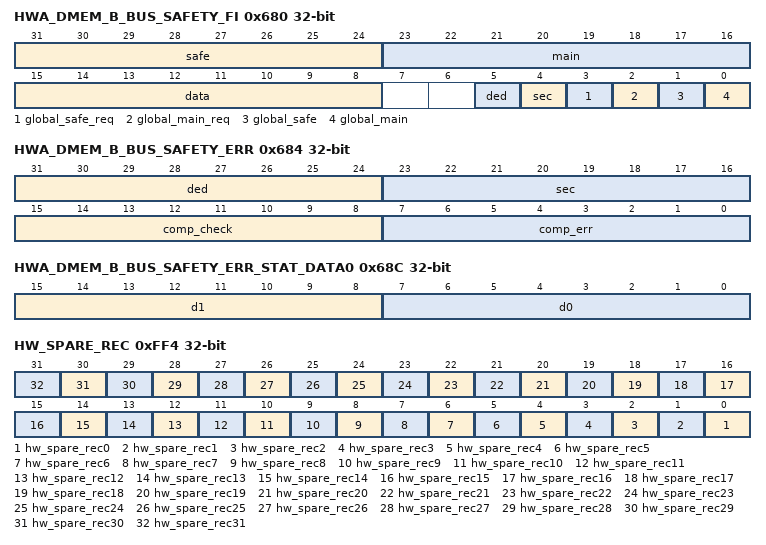
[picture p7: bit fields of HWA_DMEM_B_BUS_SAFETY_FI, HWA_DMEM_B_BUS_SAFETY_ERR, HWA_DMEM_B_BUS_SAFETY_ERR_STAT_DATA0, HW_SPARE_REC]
0x680 HWA_DMEM_B_BUS_SAFETY_FI rw
  fields as HWA_DMEM_A_BUS_SAFETY_FI
0x684 HWA_DMEM_B_BUS_SAFETY_ERR
  fields as HWA_DMEM_A_BUS_SAFETY_ERR
0x68C HWA_DMEM_B_BUS_SAFETY_ERR_STAT_DATA0
  fields as HWA_DMEM_A_BUS_SAFETY_ERR_STAT_DATA0
0x690 SW_RESTART_LOOP rw
  [0] sw_restart_loop — This is a self clearing sofware trigger bit for low priority thread . When sw_restart_loop is 1 , low priority thread is reconfigured with param_start_idx,param_end_idx,num_loops
0x694 REG_CMP_LFSRSEED_0 rw
  [28:0] REG_CMP_LFSRSEED_0 — This register is the first seed for the 29-bit LFSR used for compression
0x698 REG_CMP_LFSRSEED_1 rw
  [28:0] REG_CMP_LFSRSEED_1 — This register is the second seed for the 29-bit LFSR used for compression
0x69C REG_CMP_LFSRLOAD_0 rw
  [0] REG_CMP_LFSRLOAD_0 — Resets CMP LFSR 0 with the programmed value. This is a self clearing bit
0x6A0 REG_CMP_LFSRLOAD_1 rw
  [0] REG_CMP_LFSRLOAD_1 — Resets CMP LFSR 1 with the programmed value. This is a self clearing bit
{0xFD0+4i} HW_SPARE_RW{i} rw (i=0..3)
  [31:0] hw_spare_rw{i} — Reserved for HW R&D
{0xFE0+4i} HW_SPARE_RO{i} (i=0..3)
  [31:0] hw_spare_ro{i} — Reserved for HW R&D
0xFF0 HW_SPARE_WPH rw
  [31:0] hw_spare_wph — Reserved for HW R&D
0xFF4 HW_SPARE_REC rw
  [n] hw_spare_rec{n} (n=0..31) — Reserved for HW R&D
0x1008 LOCK0_KICK0 rw — - KICK0 component
  [31:0] ?
0x100C LOCK0_KICK1 rw — - KICK1 component
  [31:0] ?
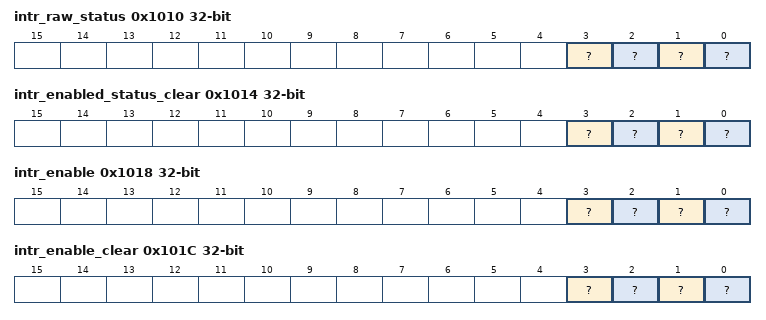
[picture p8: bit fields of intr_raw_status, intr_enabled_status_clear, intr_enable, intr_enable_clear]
0x1010 intr_raw_status rw — Interrupt Raw Status/Set Register
  [3] ? — Proxy0 access violation error. Raw status is read. Write a 1 to set the status. Writing a 0 has no effect.
  [2] ? — Kick access violation error. Raw status is read. Write a 1 to set the status. Writing a 0 has no effect.
  [1] ? — Addressing violation error. Raw status is read. Write a 1 to set the status. Writing a 0 has no effect.
  [0] ? — Protection violation error. Raw status is read. Write a 1 to set the status. Writing a 0 has no effect.
0x1014 intr_enabled_status_clear rw — Interrupt Enabled Status/Clear register
  [3] ? — Proxy0 access violation error. Enabled status is read. Write a 1 to clear the status. Writing a 0 has no effect.
  [2] ? — Kick access violation error. Enabled status is read. Write a 1 to clear the status. Writing a 0 has no effect.
  [1] ? — Addressing violation error. Enabled status is read. Write a 1 to clear the status. Writing a 0 has no effect.
  [0] ? — Protection violation error. Enabled status is read. Write a 1 to clear the status. Writing a 0 has no effect.
0x1018 intr_enable rw — Interrupt Enable register
  [3] ? — Proxy0 access violation error enable. Write a 1 to set the enable. Writing a 0 has no effect.
  [2] ? — Kick access violation error enable. Write a 1 to set the enable. Writing a 0 has no effect.
  [1] ? — Addressing violation error enable. Write a 1 to set the enable. Writing a 0 has no effect.
  [0] ? — Protection violation error enable. Write a 1 to set the enable. Writing a 0 has no effect.
0x101C intr_enable_clear rw — Interrupt Enable Clear register
  [3] ? — Proxy0 access violation error enable clear. Write a 1 to clear the enable. Writing a 0 has no effect.
  [2] ? — Kick access violation error enable clear. Write a 1 to clear the enable. Writing a 0 has no effect.
  [1] ? — Addressing violation error enable clear. Write a 1 to clear the enable. Writing a 0 has no effect.
  [0] ? — Protection violation error enable clear. Write a 1 to clear the enable. Writing a 0 has no effect.
0x1020 eoi rw
  [7:0] ? — EOI vector value. Write this with interrupt distribution value in the chip.
0x1024 fault_address
  [31:0] ? — Fault Address.
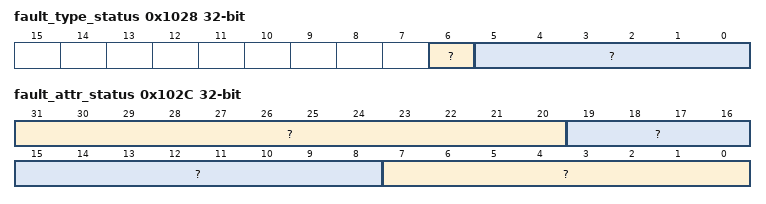
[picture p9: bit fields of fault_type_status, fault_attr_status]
0x1028 fault_type_status
  [6] ? — Non-secure access.
  [5:0] ? — Fault Type 10_0000 = Supervisor read fault - priv = 1 dir = 1 dtype != 1 01_0000 = Supervisor write fault - priv = 1 dir = 0 00_1000 = Supervisor execute fault - priv = 1 dir = 1 dtype = 1 00_0100 = User read fault - priv = 0 dir = 1 dtype = 1 00_0010 = User write fault - priv = 0 dir = 0 00_0001 = User execute fault - priv = 0 dir = 1 dtype = 1 00_0000 = No fault
0x102C fault_attr_status — Fault Attribute Status register
  [31:20] ? — XID.
  [19:8] ? — Route ID.
  [7:0] ? — Privilege ID.
0x1030 fault_clear wo
  [0] ? — Fault clear. Writing a 1 clears the current fault. Writing a 0 has no effect.
